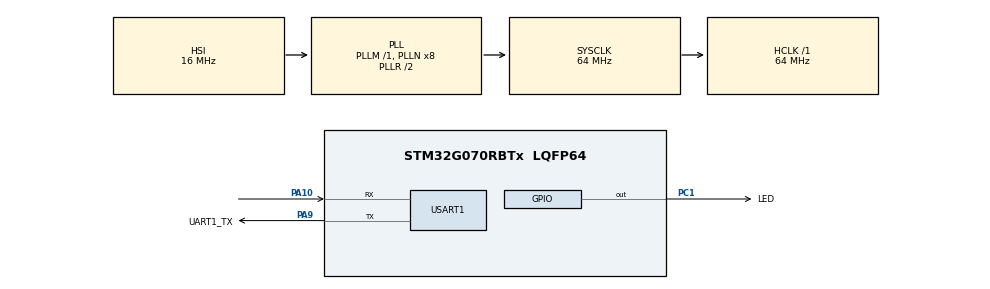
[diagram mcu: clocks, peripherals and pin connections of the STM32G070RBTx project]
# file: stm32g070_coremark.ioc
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Mcu.Family=STM32G0
Mcu.Name=STM32G070RBTx
Mcu.Package=LQFP64
PA10.Mode=Asynchronous
PA10.Signal=USART1_RX
PA13.Mode=Serial_Wire
PA13.Signal=SYS_SWDIO
PA14-BOOT0.Mode=Serial_Wire
PA14-BOOT0.Signal=SYS_SWCLK
PA9.GPIO_Label=UART1_TX
PA9.Mode=Asynchronous
PA9.Signal=USART1_TX
PC1.GPIO_Label=LED
PC1.Signal=GPIO_Output
ProjectManager.HeapSize=0x200
ProjectManager.StackSize=0xC00
ProjectManager.TargetToolchain=EWARM V8.50
RCC.ADCFreq_Value=64000000
RCC.AHBFreq_Value=64000000
RCC.CortexFreq_Value=64000000
RCC.EXTERNAL_CLOCK_VALUE=48000
RCC.HCLKFreq_Value=64000000
RCC.HSE_VALUE=8000000
RCC.HSI_VALUE=16000000
RCC.LSE_VALUE=32768
RCC.SYSCLKFreq_VALUE=64000000
RCC.SYSCLKSource=RCC_SYSCLKSOURCE_PLLCLK
RCC.VCOOutputFreq_Value=128000000
USART1.VirtualMode-Asynchronous=VM_ASYNC
VP_SYS_VS_DBSignals.Mode=DisableDeadBatterySignals
board=custom

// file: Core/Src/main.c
/* USER CODE BEGIN Header */
/**
  ******************************************************************************
  * @file           : main.c
  * @brief          : Main program body
  ******************************************************************************
  * @attention
  *
  * Copyright (c) 2022 STMicroelectronics.
  * All rights reserved.
  *
  * This software is licensed under terms that can be found in the LICENSE file
  * in the root directory of this software component.
  * If no LICENSE file comes with this software, it is provided AS-IS.
  *
  ******************************************************************************
  */
/* USER CODE END Header */
#include "main.h"

/* USER CODE BEGIN Includes */
#include "stdio.h"
/* USER CODE END Includes */

 UART_HandleTypeDef huart1;

void SystemClock_Config(void);
static void MX_GPIO_Init(void);
static void MX_USART1_UART_Init(void);

/* USER CODE BEGIN 0 */
#if defined(__CC_ARM) || (defined(__ARMCC_VERSION) && (__ARMCC_VERSION >= 6010050))
int fputc(int ch, FILE *f)
{
    HAL_UART_Transmit(&huart1, (uint8_t *)&ch, 1, HAL_MAX_DELAY);
    return ch;
}
#elif defined(__GNUC__)
int _write(int fd, char * ptr, int len)
{
  HAL_UART_Transmit(&huart1, (uint8_t *) ptr, len, HAL_MAX_DELAY);
  return len;
}
#elif defined (__ICCARM__)
#include "LowLevelIOInterface.h"
size_t __write(int handle, const unsigned char * buffer, size_t size)
{
  HAL_UART_Transmit(&huart1, (uint8_t *) buffer, size, HAL_MAX_DELAY);
  return size;
}
#endif

void SystemClock_Config_Ex(void)
{
  RCC_OscInitTypeDef RCC_OscInitStruct = {0};
  RCC_ClkInitTypeDef RCC_ClkInitStruct = {0};

  /** Configure the main internal regulator output voltage
  */
  HAL_PWREx_ControlVoltageScaling(PWR_REGULATOR_VOLTAGE_SCALE1);

  /** Initializes the RCC Oscillators according to the specified parameters
  * in the RCC_OscInitTypeDef structure.
  */
  RCC_OscInitStruct.OscillatorType = RCC_OSCILLATORTYPE_HSI;
  RCC_OscInitStruct.HSIState = RCC_HSI_ON;
  RCC_OscInitStruct.HSIDiv = RCC_HSI_DIV1;
  RCC_OscInitStruct.HSICalibrationValue = RCC_HSICALIBRATION_DEFAULT;
  RCC_OscInitStruct.PLL.PLLState = RCC_PLL_ON;
  RCC_OscInitStruct.PLL.PLLSource = RCC_PLLSOURCE_HSI;
  RCC_OscInitStruct.PLL.PLLM = RCC_PLLM_DIV1;
#if defined (SYSTEM_CLOCK_96M)
  #warning "SYSTEM_CLOCK_96M, overclock!"
  RCC_OscInitStruct.PLL.PLLN = 12;
  RCC_OscInitStruct.PLL.PLLR = RCC_PLLR_DIV2;
#elif defined (SYSTEM_CLOCK_64M)
  #warning "SYSTEM_CLOCK_64M)"
  RCC_OscInitStruct.PLL.PLLN = 8;
  RCC_OscInitStruct.PLL.PLLR = RCC_PLLR_DIV2;
#elif defined (SYSTEM_CLOCK_24M)
  #warning "SYSTEM_CLOCK_24M)"
  RCC_OscInitStruct.PLL.PLLN = 12;
  RCC_OscInitStruct.PLL.PLLR = RCC_PLLR_DIV8;
#else
  #warning "SYSTEM_CLOCK_64M)"
  RCC_OscInitStruct.PLL.PLLN = 8;
  RCC_OscInitStruct.PLL.PLLR = RCC_PLLR_DIV2;
#endif
  RCC_OscInitStruct.PLL.PLLP = RCC_PLLP_DIV2;

  if (HAL_RCC_OscConfig(&RCC_OscInitStruct) != HAL_OK)
  {
    Error_Handler();
  }

  /** Initializes the CPU, AHB and APB buses clocks
  */
  RCC_ClkInitStruct.ClockType = RCC_CLOCKTYPE_HCLK|RCC_CLOCKTYPE_SYSCLK
                              |RCC_CLOCKTYPE_PCLK1;
  RCC_ClkInitStruct.SYSCLKSource = RCC_SYSCLKSOURCE_PLLCLK;
  RCC_ClkInitStruct.AHBCLKDivider = RCC_SYSCLK_DIV1;
  RCC_ClkInitStruct.APB1CLKDivider = RCC_HCLK_DIV1;

#if defined (SYSTEM_CLOCK_64M) | (SYSTEM_CLOCK_96M)
  if (HAL_RCC_ClockConfig(&RCC_ClkInitStruct, FLASH_LATENCY_2) != HAL_OK)
#elif defined (SYSTEM_CLOCK_24M)
  if (HAL_RCC_ClockConfig(&RCC_ClkInitStruct, FLASH_LATENCY_0) != HAL_OK)
#else
  if (HAL_RCC_ClockConfig(&RCC_ClkInitStruct, FLASH_LATENCY_2) != HAL_OK)
#endif
  {
    Error_Handler();
  }
}

void platform_init(void)
{
  HAL_Init();
  SystemClock_Config_Ex();
  MX_GPIO_Init();
  MX_USART1_UART_Init();

#if defined (CACHE_OFF)
  __HAL_FLASH_INSTRUCTION_CACHE_DISABLE();
#endif

#if defined (PREFETCH_OFF)
  __HAL_FLASH_PREFETCH_BUFFER_DISABLE();
#endif

}

/* USER CODE END 0 */

void SystemClock_Config(void)
{
  RCC_OscInitTypeDef RCC_OscInitStruct = {0};
  RCC_ClkInitTypeDef RCC_ClkInitStruct = {0};

  /** Configure the main internal regulator output voltage
  */
  HAL_PWREx_ControlVoltageScaling(PWR_REGULATOR_VOLTAGE_SCALE1);

  /** Initializes the RCC Oscillators according to the specified parameters
  * in the RCC_OscInitTypeDef structure.
  */
  RCC_OscInitStruct.OscillatorType = RCC_OSCILLATORTYPE_HSI;
  RCC_OscInitStruct.HSIState = RCC_HSI_ON;
  RCC_OscInitStruct.HSIDiv = RCC_HSI_DIV1;
  RCC_OscInitStruct.HSICalibrationValue = RCC_HSICALIBRATION_DEFAULT;
  RCC_OscInitStruct.PLL.PLLState = RCC_PLL_ON;
  RCC_OscInitStruct.PLL.PLLSource = RCC_PLLSOURCE_HSI;
  RCC_OscInitStruct.PLL.PLLM = RCC_PLLM_DIV1;
  RCC_OscInitStruct.PLL.PLLN = 8;
  RCC_OscInitStruct.PLL.PLLP = RCC_PLLP_DIV2;
  RCC_OscInitStruct.PLL.PLLR = RCC_PLLR_DIV2;
  if (HAL_RCC_OscConfig(&RCC_OscInitStruct) != HAL_OK)
  {
    Error_Handler();
  }

  /** Initializes the CPU, AHB and APB buses clocks
  */
  RCC_ClkInitStruct.ClockType = RCC_CLOCKTYPE_HCLK|RCC_CLOCKTYPE_SYSCLK
                              |RCC_CLOCKTYPE_PCLK1;
  RCC_ClkInitStruct.SYSCLKSource = RCC_SYSCLKSOURCE_PLLCLK;
  RCC_ClkInitStruct.AHBCLKDivider = RCC_SYSCLK_DIV1;
  RCC_ClkInitStruct.APB1CLKDivider = RCC_HCLK_DIV1;

  if (HAL_RCC_ClockConfig(&RCC_ClkInitStruct, FLASH_LATENCY_2) != HAL_OK)
  {
    Error_Handler();
  }
}

static void MX_USART1_UART_Init(void)
{

  huart1.Instance = USART1;
  huart1.Init.BaudRate = 115200;
  huart1.Init.WordLength = UART_WORDLENGTH_8B;
  huart1.Init.StopBits = UART_STOPBITS_1;
  huart1.Init.Parity = UART_PARITY_NONE;
  huart1.Init.Mode = UART_MODE_TX_RX;
  huart1.Init.HwFlowCtl = UART_HWCONTROL_NONE;
  huart1.Init.OverSampling = UART_OVERSAMPLING_16;
  huart1.Init.OneBitSampling = UART_ONE_BIT_SAMPLE_DISABLE;
  huart1.Init.ClockPrescaler = UART_PRESCALER_DIV1;
  huart1.AdvancedInit.AdvFeatureInit = UART_ADVFEATURE_NO_INIT;
  if (HAL_UART_Init(&huart1) != HAL_OK)
  {
    Error_Handler();
  }
  if (HAL_UARTEx_SetTxFifoThreshold(&huart1, UART_TXFIFO_THRESHOLD_1_8) != HAL_OK)
  {
    Error_Handler();
  }
  if (HAL_UARTEx_SetRxFifoThreshold(&huart1, UART_RXFIFO_THRESHOLD_1_8) != HAL_OK)
  {
    Error_Handler();
  }
  if (HAL_UARTEx_DisableFifoMode(&huart1) != HAL_OK)
  {
    Error_Handler();
  }

}

static void MX_GPIO_Init(void)
{
  GPIO_InitTypeDef GPIO_InitStruct = {0};

  /* GPIO Ports Clock Enable */
  __HAL_RCC_GPIOC_CLK_ENABLE();
  __HAL_RCC_GPIOA_CLK_ENABLE();

  /*Configure GPIO pin Output Level */
  HAL_GPIO_WritePin(LED_GPIO_Port, LED_Pin, GPIO_PIN_RESET);

  /*Configure GPIO pin : LED_Pin */
  GPIO_InitStruct.Pin = LED_Pin;
  GPIO_InitStruct.Mode = GPIO_MODE_OUTPUT_PP;
  GPIO_InitStruct.Pull = GPIO_NOPULL;
  GPIO_InitStruct.Speed = GPIO_SPEED_FREQ_LOW;
  HAL_GPIO_Init(LED_GPIO_Port, &GPIO_InitStruct);

}

void Error_Handler(void)
{
  __disable_irq();
  while (1)
  {
  }
}
